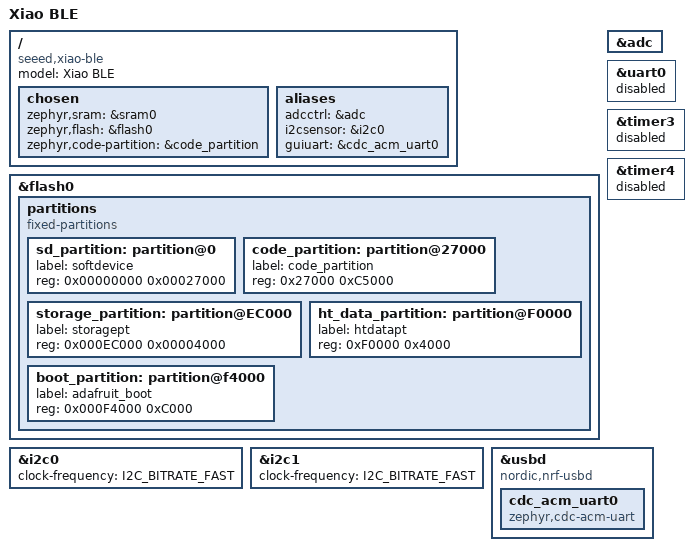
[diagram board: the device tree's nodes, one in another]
/ {
	model = "Xiao BLE";
	compatible = "seeed,xiao-ble";

	chosen {
		/delete-property/ zephyr,console;
		/delete-property/ zephyr,shell-uart;
		/delete-property/ zephyr,uart-mcumgr;
		/delete-property/ zephyr,bt-mon-uart;
		/delete-property/ zephyr,bt-c2h-uart;
    /delete-property/ zephyr,ieee802154;
		zephyr,sram = &sram0;
		zephyr,flash = &flash0;
		zephyr,code-partition = &code_partition;

		// Uncomment the below line for kernel logging to a second USB CDC port
		// Also uncomment the extra cdc at the bottom of the file
		//   zephyr,console = &cdc_acm_uart1;
	};

  aliases {
		adcctrl = &adc;
		i2csensor = &i2c0;
		//i2csensorext = &i2c1;
		guiuart = &cdc_acm_uart0;
  };
};

/* Flash Layout
 *    Soft Dev      0x00000 - 0x27000 (Size 0x27000)
 *    Code          0x27000 - 0xEC000 (Size 0xC5000)
 *    NVM Data      0xEC000 - 0xF0000 (Size 0x4000)
 *    HT Settings   0xF0000 - 0xF4000 (Size 0x4000)
 *    Boot          0xF4000 - 0x100000 (Size 0xC000)
 */

/delete-node/ &storage_partition;

&flash0 {
	partitions {
		compatible = "fixed-partitions";
		#address-cells = <1>;
		#size-cells = <1>;

		sd_partition: partition@0 {
			label = "softdevice";
			reg = <0x00000000 0x00027000>;
		};

		code_partition: partition@27000 {
			label = "code_partition";
			reg = <0x27000 0xC5000>;
		};

		storage_partition: partition@EC000 {
			label = "storagept";
			reg = <0x000EC000 0x00004000>;
		};

		ht_data_partition: partition@F0000 {
			label = "htdatapt";
			reg = <0xF0000 0x4000>;
		};

		boot_partition: partition@f4000 {
			label = "adafruit_boot";
			reg = <0x000F4000 0xC000>;
		};
	};
};

&adc {
	status = "okay";
};

// HT doesn't use Zephyr's driver here
/delete-node/ &lsm6ds3tr_c;

&i2c0 {
	clock-frequency = <I2C_BITRATE_FAST>;
};

&i2c1 {
	clock-frequency = <I2C_BITRATE_FAST>;
};

&uart0 {
	status = "disabled";
};

/* Disable Timer3, used by PPM output
 */
&timer3 {
    status = "disabled";
};

/* Disable Timer4, used by PPM input
 */
&timer4 {
    status = "disabled";
};

/delete-node/ &usb_cdc_acm_uart; /* We use cdc_acm_uart0 */

zephyr_udc0: &usbd {
	compatible = "nordic,nrf-usbd";
	status = "okay";
  cdc_acm_uart0: cdc_acm_uart0 {
	compatible = "zephyr,cdc-acm-uart";
	};

  // Uncomment the below lines for kernel logging to a second USB CDC port
	/*
	cdc_acm_uart1: cdc_acm_uart1 {
		compatible = "zephyr,cdc-acm-uart";
	};
	*/
};



